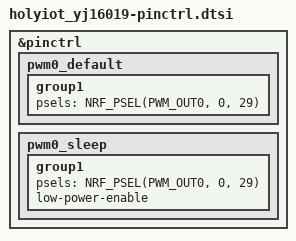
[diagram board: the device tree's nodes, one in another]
/*
 * Copyright (c) 2022 Nordic Semiconductor
 * SPDX-License-Identifier: Apache-2.0
 */

&pinctrl {
	pwm0_default: pwm0_default {
		group1 {
			psels = <NRF_PSEL(PWM_OUT0, 0, 29)>;
		};
	};

	pwm0_sleep: pwm0_sleep {
		group1 {
			psels = <NRF_PSEL(PWM_OUT0, 0, 29)>;
			low-power-enable;
		};
	};

};
